# netx90_app register map
File version: 1.0
CPU: CM4 r0p1, little endian, MPU, FPU, 4 interrupt priority bits, 78 interrupts
Registers are 32-bit, read-write, reset 0x0 unless marked. A register's access mark holds for its fields unless they carry their own. Offsets are from the block's base; [hi:lo] are bit positions; {n}, {i} and the like mark numbered series; 'fields as' and 'values as' point back to an identical list.

## xpic_app_regs
Base 0xFF884000
{0x0+4i} xpic_r{i} (i=0..7) — xPIC work register for indirect addressing
  [31:0] r{i} — Work Register {i}
{0x20+4i} xpic_usr{i} (i=0..4) — xPIC user Register additional work register
  [31:0] usr{i} — User Register {i}
0x34 xpic_pc reset 0xFFFFFFFC — xPIC Program Counter Shared in xPIC 64_BIT_MUL_TARGET mode with usr32 (w mode)
  [31:0] pc — Program Counter (dword address inside DPRAM)
0x38 xpic_stat — Processor Status Register
  [31:0] stat — no field descpription
0x3C xpic_zero — Zero Register Shared in xPIC 64_BIT_MUL_TARGET mode with usr10 (w mode)
  [31:0] zero — Always Zero

## vic_xpic_app
Base 0xFF900000
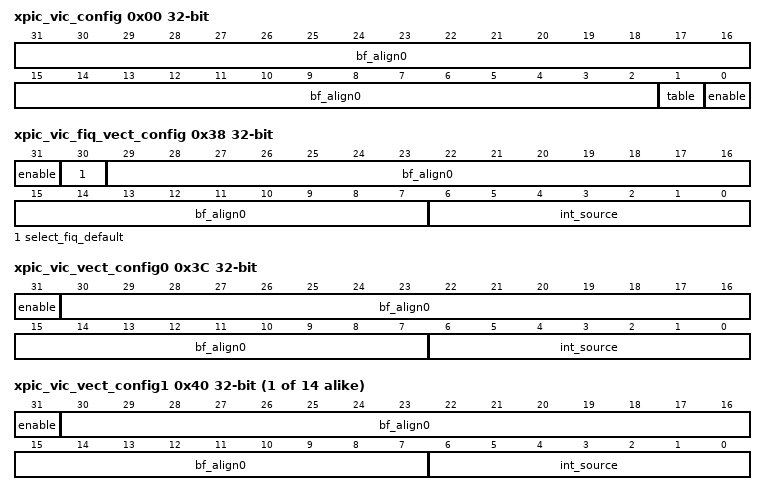
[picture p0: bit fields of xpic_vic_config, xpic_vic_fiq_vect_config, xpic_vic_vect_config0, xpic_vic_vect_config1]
0x00 xpic_vic_config (reset mask 0x3) — XPIC VIC Configuration register
  [31:2] bf_align0 — bitField alignment value for aeabi compatibility
  [1] table — use far or near Table 0 = Base Pointer Addr for IRQ Jmp Table + (n*4) DWORD Table 1 = Base Pointer Addr for IRQ Jmp Table + (n*16) 4 DWORD Table n = IRQ vector number
  [0] enable — global enable of xPIC VIC (0: disable/ 1: enable)
{0x4+4i} xpic_vic_raw_intr{i} ro (i=0..2) — XPIC VIC Raw{i} interrupt status register see netx4000_irq doc
  [31:0] irqs — see netx doc
{0x10+4i} xpic_vic_softint{i}_set (i=0..2) — XPIC VIC Software{i} interrupt set register: Read status or set IRQ by writing '1' to the appropriate bit.
  [31:0] irqs — see netx doc
{0x1C+4i} xpic_vic_softint{i}_reset (i=0..2) — XPIC VIC Software{i} interrupt reset register: Read status or reset IRQ by writing '1' to the appropriate bit.
  [31:0] irqs — see netx doc
0x28 xpic_vic_fiq_addr — XPIC VIC FIQ Vector address 0 register
  [31:0] val — FIQ handler address
0x2C xpic_vic_irq_addr — XPIC VIC normal IRQ address register
  [31:0] val — IRQ handler address
0x30 xpic_vic_vector_addr ro — XPIC VIC IRQ Vector address
  [31:0] val — IRQ vector address read access get actuel highest prior IRQ read access get adr_xpic_vic_table_base_addr + IRQ Number * (4/16)
0x34 xpic_vic_table_base_addr — XPIC VIC IRQ TABLE ADDRESS BASE POINTER
  [31:0] val — IRQ Table base address the Base Pointer Addr for IRQ Jmp Table
0x38 xpic_vic_fiq_vect_config (reset mask 0xC000007F) — no Register description
  [31] enable — vector interrupt enable
  [30] select_fiq_default — 1 = select default vector for fiq (overwrite the int_source selection)
  [29:7] bf_align0 — bitField alignment value for aeabi compatibility
  [6:0] int_source — INT_SOURCE 0-95
0x3C xpic_vic_vect_config0 (reset mask 0x8000007F) — highest priority
  [31] enable — vector interrupt enable
  [30:7] bf_align0 — bitField alignment value for aeabi compatibility
  [6:0] int_source — INT_SOURCE 0-95
{0x3C+4i} xpic_vic_vect_config{i} (reset mask 0x8000007F) (i=1..14) — no Register description
  fields as xpic_vic_vect_config0
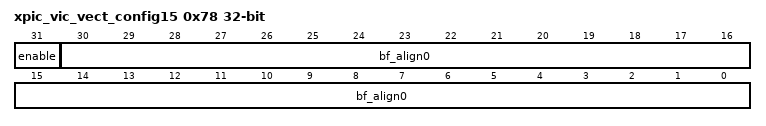
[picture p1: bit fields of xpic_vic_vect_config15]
0x78 xpic_vic_vect_config15 (reset mask 0x80000000) — XPIC default interrupt vector, all interrupt sources (wired-OR) select with default interrupt vector register lowest priority
  [31] enable — vector interrupt enable
  [30:0] bf_align0 — bitField alignment value for aeabi compatibility
0x7C xpic_vic_default0 — XPIC default interrupt vector select0
  [31:0] val — select int0 - int31 (wired-OR) 1-selected 0-not selected
0x80 xpic_vic_default1 — XPIC default interrupt vector select1
  [31:0] val — select int32 - int63 (wired-OR) 1-selected 0-not selected
0x84 xpic_vic_default2 — XPIC default interrupt vector select1
  [31:0] val — select int64 - int95 (wired-OR) 1-selected 0-not selected
0x88 xpic_vic_fiq_default0 — XPIC default interrupt vector select0 for fiq
  fields as xpic_vic_default0
0x8C xpic_vic_fiq_default1 — XPIC default interrupt vector select1 for fiq
  fields as xpic_vic_default1
0x90 xpic_vic_fiq_default2 — XPIC default interrupt vector select1 for fiq
  fields as xpic_vic_default2
